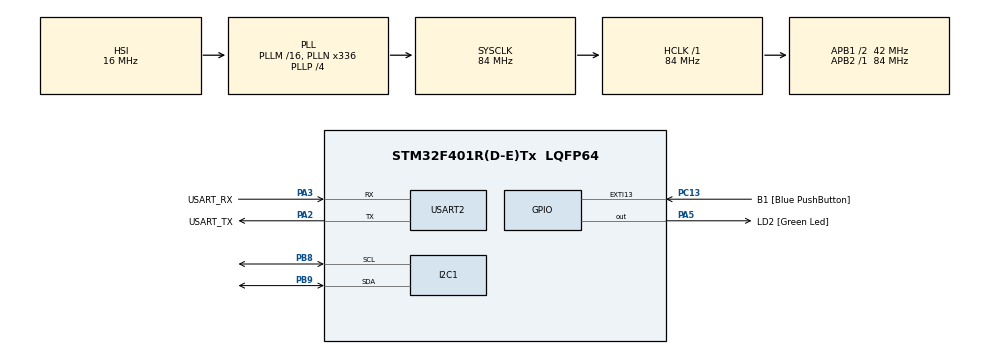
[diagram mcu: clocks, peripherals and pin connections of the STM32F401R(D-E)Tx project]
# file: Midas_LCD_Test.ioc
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Mcu.Family=STM32F4
Mcu.Name=STM32F401R(D-E)Tx
Mcu.Package=LQFP64
NVIC.PriorityGroup=NVIC_PRIORITYGROUP_4
PA13.GPIO_Label=TMS
PA13.Mode=Trace_Asynchronous_SW
PA13.Signal=SYS_JTMS-SWDIO
PA14.GPIO_Label=TCK
PA14.Mode=Trace_Asynchronous_SW
PA14.Signal=SYS_JTCK-SWCLK
PA2.GPIO_Label=USART_TX
PA2.GPIO_Mode=GPIO_MODE_AF_PP
PA2.GPIO_PuPd=GPIO_NOPULL
PA2.GPIO_Speed=GPIO_SPEED_FREQ_LOW
PA2.Mode=Asynchronous
PA2.Signal=USART2_TX
PA3.GPIO_Label=USART_RX
PA3.GPIO_Mode=GPIO_MODE_AF_PP
PA3.GPIO_PuPd=GPIO_NOPULL
PA3.GPIO_Speed=GPIO_SPEED_FREQ_LOW
PA3.Mode=Asynchronous
PA3.Signal=USART2_RX
PA5.GPIO_Label=LD2 [Green Led]
PA5.GPIO_Mode=GPIO_MODE_OUTPUT_PP
PA5.GPIO_PuPd=GPIO_NOPULL
PA5.GPIO_Speed=GPIO_SPEED_FREQ_LOW
PA5.Signal=GPIO_Output
PB3.GPIO_Label=SWO
PB3.Mode=Trace_Asynchronous_SW
PB3.Signal=SYS_JTDO-SWO
PB8.Mode=I2C
PB8.Signal=I2C1_SCL
PB9.Mode=I2C
PB9.Signal=I2C1_SDA
PC13-ANTI_TAMP.GPIO_Label=B1 [Blue PushButton]
PC13-ANTI_TAMP.GPIO_ModeDefaultEXTI=GPIO_MODE_IT_FALLING
PC13-ANTI_TAMP.GPIO_PuPd=GPIO_NOPULL
PC13-ANTI_TAMP.Signal=GPXTI13
PC14-OSC32_IN.Mode=LSE-External-Oscillator
PC14-OSC32_IN.Signal=RCC_OSC32_IN
PC15-OSC32_OUT.Mode=LSE-External-Oscillator
PC15-OSC32_OUT.Signal=RCC_OSC32_OUT
PH0\ -\ OSC_IN.Mode=HSE-External-Clock-Source
PH0\ -\ OSC_IN.Signal=RCC_OSC_IN
PH1\ -\ OSC_OUT.Mode=HSE-External-Clock-Source
PH1\ -\ OSC_OUT.Signal=RCC_OSC_OUT
ProjectManager.HeapSize=0x200
ProjectManager.StackSize=0x400
ProjectManager.TargetToolchain=CMake
RCC.48MHZClocksFreq_Value=48000000
RCC.AHBFreq_Value=84000000
RCC.APB1CLKDivider=RCC_HCLK_DIV2
RCC.APB1Freq_Value=42000000
RCC.APB1TimFreq_Value=84000000
RCC.APB2Freq_Value=84000000
RCC.APB2TimFreq_Value=84000000
RCC.CortexFreq_Value=84000000
RCC.HCLKFreq_Value=84000000
RCC.HSE_VALUE=8000000
RCC.HSI_VALUE=16000000
RCC.PLLN=336
RCC.PLLP=RCC_PLLP_DIV4
RCC.PLLQ=7
RCC.SYSCLKFreq_VALUE=84000000
RCC.SYSCLKSource=RCC_SYSCLKSOURCE_PLLCLK
RCC.VCOOutputFreq_Value=336000000
USART2.VirtualMode=VM_ASYNC
board=NUCLEO-F401RE

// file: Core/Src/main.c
/* USER CODE BEGIN Header */
/**
  ******************************************************************************
  * @file           : main.c
  * @brief          : Main program body
  ******************************************************************************
  * @attention
  *
  * Copyright (c) 2026 STMicroelectronics.
  * All rights reserved.
  *
  * This software is licensed under terms that can be found in the LICENSE file
  * in the root directory of this software component.
  * If no LICENSE file comes with this software, it is provided AS-IS.
  *
  ******************************************************************************
  */
/* USER CODE END Header */
#include "main.h"

I2C_HandleTypeDef hi2c1;

UART_HandleTypeDef huart2;

#define SSD1306_ADDR       (0x3C << 1)
#define SSD1306_WIDTH      128
#define SSD1306_HEIGHT     64

static uint8_t oled_buffer[SSD1306_WIDTH * SSD1306_HEIGHT / 8];

/* 5x7 font - characters 0x20 to 0x5A */
static const uint8_t font5x7[][5] =
{
    {0x00,0x00,0x00,0x00,0x00}, // space
    {0x00,0x00,0x5F,0x00,0x00}, // !
    {0x00,0x07,0x00,0x07,0x00}, // "
    {0x14,0x7F,0x14,0x7F,0x14}, // #
    {0x24,0x2A,0x7F,0x2A,0x12}, // $
    {0x23,0x13,0x08,0x64,0x62}, // %
    {0x36,0x49,0x55,0x22,0x50}, // &
    {0x00,0x05,0x03,0x00,0x00}, // '
    {0x00,0x1C,0x22,0x41,0x00}, // (
    {0x00,0x41,0x22,0x1C,0x00}, // )
    {0x14,0x08,0x3E,0x08,0x14}, // *
    {0x08,0x08,0x3E,0x08,0x08}, // +
    {0x00,0x50,0x30,0x00,0x00}, // ,
    {0x08,0x08,0x08,0x08,0x08}, // -
    {0x00,0x60,0x60,0x00,0x00}, // .
    {0x20,0x10,0x08,0x04,0x02}, // /
    {0x3E,0x51,0x49,0x45,0x3E}, // 0
    {0x00,0x42,0x7F,0x40,0x00}, // 1
    {0x42,0x61,0x51,0x49,0x46}, // 2
    {0x21,0x41,0x45,0x4B,0x31}, // 3
    {0x18,0x14,0x12,0x7F,0x10}, // 4
    {0x27,0x45,0x45,0x45,0x39}, // 5
    {0x3C,0x4A,0x49,0x49,0x30}, // 6
    {0x01,0x71,0x09,0x05,0x03}, // 7
    {0x36,0x49,0x49,0x49,0x36}, // 8
    {0x06,0x49,0x49,0x29,0x1E}, // 9
    {0x00,0x36,0x36,0x00,0x00}, // :
    {0x00,0x56,0x36,0x00,0x00}, // ;
    {0x08,0x14,0x22,0x41,0x00}, // <
    {0x14,0x14,0x14,0x14,0x14}, // =
    {0x00,0x41,0x22,0x14,0x08}, // >
    {0x02,0x01,0x51,0x09,0x06}, // ?
    {0x32,0x49,0x79,0x41,0x3E}, // @
    {0x7E,0x11,0x11,0x11,0x7E}, // A
    {0x7F,0x49,0x49,0x49,0x36}, // B
    {0x3E,0x41,0x41,0x41,0x22}, // C
    {0x7F,0x41,0x41,0x22,0x1C}, // D
    {0x7F,0x49,0x49,0x49,0x41}, // E
    {0x7F,0x09,0x09,0x09,0x01}, // F
    {0x3E,0x41,0x49,0x49,0x7A}, // G
    {0x7F,0x08,0x08,0x08,0x7F}, // H
    {0x00,0x41,0x7F,0x41,0x00}, // I
    {0x20,0x40,0x41,0x3F,0x01}, // J
    {0x7F,0x08,0x14,0x22,0x41}, // K
    {0x7F,0x40,0x40,0x40,0x40}, // L
    {0x7F,0x02,0x0C,0x02,0x7F}, // M
    {0x7F,0x04,0x08,0x10,0x7F}, // N
    {0x3E,0x41,0x41,0x41,0x3E}, // O
    {0x7F,0x09,0x09,0x09,0x06}, // P
    {0x3E,0x41,0x51,0x21,0x5E}, // Q
    {0x7F,0x09,0x19,0x29,0x46}, // R
    {0x46,0x49,0x49,0x49,0x31}, // S
    {0x01,0x01,0x7F,0x01,0x01}, // T
    {0x3F,0x40,0x40,0x40,0x3F}, // U
    {0x1F,0x20,0x40,0x20,0x1F}, // V
    {0x3F,0x40,0x38,0x40,0x3F}, // W
    {0x63,0x14,0x08,0x14,0x63}, // X
    {0x07,0x08,0x70,0x08,0x07}, // Y
    {0x61,0x51,0x49,0x45,0x43}  // Z
};

void SystemClock_Config(void);
static void MX_GPIO_Init(void);
static void MX_I2C1_Init(void);
static void MX_USART2_UART_Init(void);

static void OLED_WriteCommand(uint8_t command);
static void OLED_Init(void);
static void OLED_Clear(void);
static void OLED_Update(void);
static void OLED_DrawChar(uint8_t x, uint8_t y, char c);
static void OLED_DrawString(uint8_t x, uint8_t y, const char *str);

static void OLED_WriteCommand(uint8_t command)
{
    uint8_t data[2];

    data[0] = 0x00;
    data[1] = command;

    HAL_I2C_Master_Transmit(
        &hi2c1,
        SSD1306_ADDR,
        data,
        2,
        HAL_MAX_DELAY
    );
}

static void OLED_Init(void)
{
    HAL_Delay(100);

    OLED_WriteCommand(0xAE); // Display OFF

    OLED_WriteCommand(0xD5);
    OLED_WriteCommand(0x80);

    OLED_WriteCommand(0xA8);
    OLED_WriteCommand(0x3F);

    OLED_WriteCommand(0xD3);
    OLED_WriteCommand(0x00);

    OLED_WriteCommand(0x40);

    OLED_WriteCommand(0x8D);
    OLED_WriteCommand(0x14);

    OLED_WriteCommand(0x20);
    OLED_WriteCommand(0x00); // Horizontal addressing mode

    OLED_WriteCommand(0xA1);
    OLED_WriteCommand(0xC8);

    OLED_WriteCommand(0xDA);
    OLED_WriteCommand(0x12);

    OLED_WriteCommand(0x81);
    OLED_WriteCommand(0x7F);

    OLED_WriteCommand(0xD9);
    OLED_WriteCommand(0xF1);

    OLED_WriteCommand(0xDB);
    OLED_WriteCommand(0x40);

    OLED_WriteCommand(0xA4);
    OLED_WriteCommand(0xA6);

    OLED_WriteCommand(0xAF); // Display ON

    OLED_Clear();
    OLED_Update();
}

static void OLED_Clear(void)
{
    for (uint16_t i = 0; i < sizeof(oled_buffer); i++)
    {
        oled_buffer[i] = 0x00;
    }
}

static void OLED_Update(void)
{
    uint8_t data[129];

    data[0] = 0x40;

    for (uint8_t page = 0; page < 8; page++)
    {
        OLED_WriteCommand(0xB0 + page);
        OLED_WriteCommand(0x00);
        OLED_WriteCommand(0x10);

        for (uint8_t col = 0; col < 128; col++)
        {
            data[col + 1] =
                oled_buffer[(page * 128) + col];
        }

        HAL_I2C_Master_Transmit(
            &hi2c1,
            SSD1306_ADDR,
            data,
            129,
            HAL_MAX_DELAY
        );
    }
}

static void OLED_DrawChar(uint8_t x, uint8_t y, char c)
{
    if (c < ' ' || c > 'Z')
        return;

    uint8_t index = c - ' ';

    for (uint8_t i = 0; i < 5; i++)
    {
        uint8_t column = font5x7[index][i];

        for (uint8_t bit = 0; bit < 7; bit++)
        {
            if (column & (1 << bit))
            {
                uint8_t px = x + i;
                uint8_t py = y + bit;

                if (px < 128 && py < 64)
                {
                    oled_buffer[(py / 8) * 128 + px]
                        |= (1 << (py % 8));
                }
            }
        }
    }
}

static void OLED_DrawString(uint8_t x, uint8_t y, const char *str)
{
    while (*str)
    {
        OLED_DrawChar(x, y, *str);
        x += 6;

        if (x > 122)
        {
            x = 0;
            y += 8;
        }

        if (y >= 64)
            break;

        str++;
    }
}

int main(void)
{

  /* MCU Configuration--------------------------------------------------------*/

  /* Reset of all peripherals, Initializes the Flash interface and the Systick. */
  HAL_Init();

  /* Configure the system clock */
  SystemClock_Config();

  /* Initialize all configured peripherals */
  MX_GPIO_Init();
  MX_I2C1_Init();
  MX_USART2_UART_Init();
  /* USER CODE BEGIN 2 */
  HAL_Delay(100);

  OLED_Init();

  OLED_Clear();

  OLED_DrawString(0, 0, "HELLO ESK8!");
  OLED_DrawString(0, 16, "STM32F401RE");
  OLED_DrawString(0, 32, "OLED TEST");
  OLED_DrawString(0, 48, "I2C OK");

  OLED_Update();
  /* USER CODE END 2 */

  /* Infinite loop */
  /* USER CODE BEGIN WHILE */
  while (1)
  {
    HAL_GPIO_TogglePin(LD2_GPIO_Port, LD2_Pin);
    HAL_Delay(500);
    /* USER CODE END WHILE */

  }
}

void SystemClock_Config(void)
{
  RCC_OscInitTypeDef RCC_OscInitStruct = {0};
  RCC_ClkInitTypeDef RCC_ClkInitStruct = {0};

  /** Configure the main internal regulator output voltage
  */
  __HAL_RCC_PWR_CLK_ENABLE();
  __HAL_PWR_VOLTAGESCALING_CONFIG(PWR_REGULATOR_VOLTAGE_SCALE2);

  /** Initializes the RCC Oscillators according to the specified parameters
  * in the RCC_OscInitTypeDef structure.
  */
  RCC_OscInitStruct.OscillatorType = RCC_OSCILLATORTYPE_HSI;
  RCC_OscInitStruct.HSIState = RCC_HSI_ON;
  RCC_OscInitStruct.HSICalibrationValue = RCC_HSICALIBRATION_DEFAULT;
  RCC_OscInitStruct.PLL.PLLState = RCC_PLL_ON;
  RCC_OscInitStruct.PLL.PLLSource = RCC_PLLSOURCE_HSI;
  RCC_OscInitStruct.PLL.PLLM = 16;
  RCC_OscInitStruct.PLL.PLLN = 336;
  RCC_OscInitStruct.PLL.PLLP = RCC_PLLP_DIV4;
  RCC_OscInitStruct.PLL.PLLQ = 7;
  if (HAL_RCC_OscConfig(&RCC_OscInitStruct) != HAL_OK)
  {
    Error_Handler();
  }

  /** Initializes the CPU, AHB and APB buses clocks
  */
  RCC_ClkInitStruct.ClockType = RCC_CLOCKTYPE_HCLK|RCC_CLOCKTYPE_SYSCLK
                              |RCC_CLOCKTYPE_PCLK1|RCC_CLOCKTYPE_PCLK2;
  RCC_ClkInitStruct.SYSCLKSource = RCC_SYSCLKSOURCE_PLLCLK;
  RCC_ClkInitStruct.AHBCLKDivider = RCC_SYSCLK_DIV1;
  RCC_ClkInitStruct.APB1CLKDivider = RCC_HCLK_DIV2;
  RCC_ClkInitStruct.APB2CLKDivider = RCC_HCLK_DIV1;

  if (HAL_RCC_ClockConfig(&RCC_ClkInitStruct, FLASH_LATENCY_2) != HAL_OK)
  {
    Error_Handler();
  }
}

static void MX_I2C1_Init(void)
{

  hi2c1.Instance = I2C1;
  hi2c1.Init.ClockSpeed = 100000;
  hi2c1.Init.DutyCycle = I2C_DUTYCYCLE_2;
  hi2c1.Init.OwnAddress1 = 0;
  hi2c1.Init.AddressingMode = I2C_ADDRESSINGMODE_7BIT;
  hi2c1.Init.DualAddressMode = I2C_DUALADDRESS_DISABLE;
  hi2c1.Init.OwnAddress2 = 0;
  hi2c1.Init.GeneralCallMode = I2C_GENERALCALL_DISABLE;
  hi2c1.Init.NoStretchMode = I2C_NOSTRETCH_DISABLE;
  if (HAL_I2C_Init(&hi2c1) != HAL_OK)
  {
    Error_Handler();
  }

}

static void MX_USART2_UART_Init(void)
{

  huart2.Instance = USART2;
  huart2.Init.BaudRate = 115200;
  huart2.Init.WordLength = UART_WORDLENGTH_8B;
  huart2.Init.StopBits = UART_STOPBITS_1;
  huart2.Init.Parity = UART_PARITY_NONE;
  huart2.Init.Mode = UART_MODE_TX_RX;
  huart2.Init.HwFlowCtl = UART_HWCONTROL_NONE;
  huart2.Init.OverSampling = UART_OVERSAMPLING_16;
  if (HAL_UART_Init(&huart2) != HAL_OK)
  {
    Error_Handler();
  }

}

static void MX_GPIO_Init(void)
{
  GPIO_InitTypeDef GPIO_InitStruct = {0};

  /* GPIO Ports Clock Enable */
  __HAL_RCC_GPIOC_CLK_ENABLE();
  __HAL_RCC_GPIOH_CLK_ENABLE();
  __HAL_RCC_GPIOA_CLK_ENABLE();
  __HAL_RCC_GPIOB_CLK_ENABLE();

  /*Configure GPIO pin Output Level */
  HAL_GPIO_WritePin(LD2_GPIO_Port, LD2_Pin, GPIO_PIN_RESET);

  /*Configure GPIO pin : B1_Pin */
  GPIO_InitStruct.Pin = B1_Pin;
  GPIO_InitStruct.Mode = GPIO_MODE_IT_FALLING;
  GPIO_InitStruct.Pull = GPIO_NOPULL;
  HAL_GPIO_Init(B1_GPIO_Port, &GPIO_InitStruct);

  /*Configure GPIO pin : LD2_Pin */
  GPIO_InitStruct.Pin = LD2_Pin;
  GPIO_InitStruct.Mode = GPIO_MODE_OUTPUT_PP;
  GPIO_InitStruct.Pull = GPIO_NOPULL;
  GPIO_InitStruct.Speed = GPIO_SPEED_FREQ_LOW;
  HAL_GPIO_Init(LD2_GPIO_Port, &GPIO_InitStruct);

}

void Error_Handler(void)
{
  __disable_irq();
  while (1)
  {
  }
}
